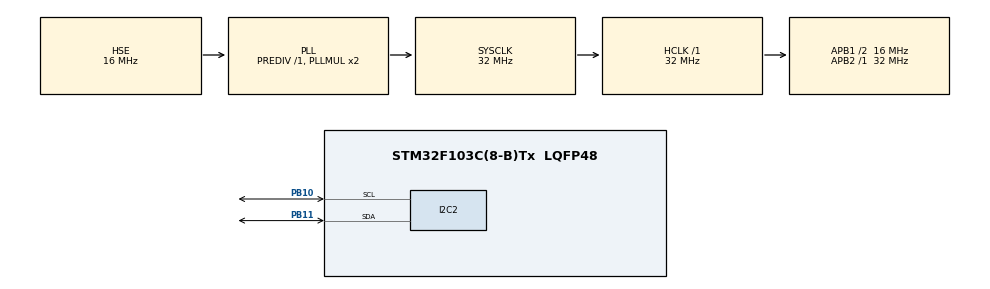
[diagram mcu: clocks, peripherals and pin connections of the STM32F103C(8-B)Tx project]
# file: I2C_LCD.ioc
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Mcu.Family=STM32F1
Mcu.Name=STM32F103C(8-B)Tx
Mcu.Package=LQFP48
NVIC.PriorityGroup=NVIC_PRIORITYGROUP_4
NVIC.TIM2_IRQn=true\:0\:0\:false\:false\:true\:true\:true\:true
PB10.Mode=I2C
PB10.Signal=I2C2_SCL
PB11.Mode=I2C
PB11.Signal=I2C2_SDA
PD0-OSC_IN.Mode=HSE-External-Oscillator
PD0-OSC_IN.Signal=RCC_OSC_IN
PD1-OSC_OUT.Mode=HSE-External-Oscillator
PD1-OSC_OUT.Signal=RCC_OSC_OUT
ProjectManager.HeapSize=0x200
ProjectManager.StackSize=0x400
ProjectManager.TargetToolchain=STM32CubeIDE
RCC.AHBFreq_Value=32000000
RCC.APB1CLKDivider=RCC_HCLK_DIV2
RCC.APB1Freq_Value=16000000
RCC.APB1TimFreq_Value=32000000
RCC.APB2Freq_Value=32000000
RCC.APB2TimFreq_Value=32000000
RCC.HCLKFreq_Value=32000000
RCC.HSE_VALUE=16000000
RCC.PLLSourceVirtual=RCC_PLLSOURCE_HSE
RCC.SYSCLKFreq_VALUE=32000000
RCC.SYSCLKSource=RCC_SYSCLKSOURCE_PLLCLK
RCC.USBFreq_Value=32000000
TIM2.Period=999
TIM2.Prescaler=32000
VP_SYS_VS_ND.Mode=No_Debug
VP_TIM2_VS_ClockSourceINT.Mode=Internal
board=custom

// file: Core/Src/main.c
/* USER CODE BEGIN Header */
/**
  ******************************************************************************
  * @file           : main.c
  * @brief          : Main program body
  ******************************************************************************
  * @attention
  *
  * Copyright (c) 2024 STMicroelectronics.
  * All rights reserved.
  *
  * This software is licensed under terms that can be found in the LICENSE file
  * in the root directory of this software component.
  * If no LICENSE file comes with this software, it is provided AS-IS.
  *
  ******************************************************************************
  */
/* USER CODE END Header */
#include "main.h"

/* USER CODE BEGIN Includes */
#include <stdint.h>
#include <stdio.h>
/* USER CODE END Includes */

/* USER CODE BEGIN PD */
//LCD Voreinstellungen
#define LCD_ADDR (0x27 << 1)
#define PIN_RS (1 << 0)
#define PIN_EN (1 << 2)
#define PIN_BL (1 << 3)
/* USER CODE END PD */

I2C_HandleTypeDef hi2c2;

TIM_HandleTypeDef htim2;

/* USER CODE BEGIN PV */
volatile uint8_t u1_TIM_Counter = 0;
/* USER CODE END PV */

void SystemClock_Config(void);
static void MX_GPIO_Init(void);
static void MX_I2C2_Init(void);
static void MX_TIM2_Init(void);
/* USER CODE BEGIN PFP */
//LCD-Funktionen

void send_LCD(uint8_t u1_data, uint8_t flag);
void send_LCD_CMD(uint8_t u1_data);
void send_LCD_TXT(uint8_t u1_data);
/* USER CODE END PFP */

int main(void)
{

  /* MCU Configuration--------------------------------------------------------*/

  /* Reset of all peripherals, Initializes the Flash interface and the Systick. */
  HAL_Init();

  /* Configure the system clock */
  SystemClock_Config();

  /* Initialize all configured peripherals */
  MX_GPIO_Init();
  MX_I2C2_Init();
  MX_TIM2_Init();
  /* USER CODE BEGIN 2 */
  //LCD-Konfiguration
  send_LCD_CMD(0x30);
  send_LCD_CMD(0xC);
  send_LCD_CMD(0x2);
  send_LCD_CMD(0x1);
  send_LCD_CMD(0x0E);

  //Buffer für obere Zeile
  unsigned char u1_charBuffer_top[16];
  //Buffer für untere Zeile
  unsigned char u1_charBuffer_down[16];

  //Begrüßungstext
  uint16_t u2_bytes_top  = sprintf((char*) &u1_charBuffer_top, "Hello");
  uint16_t u2_bytes_down = sprintf((char*) &u1_charBuffer_down, "Student");
  //obere Reihe
  send_LCD_CMD(0x80);
  for (uint8_t u1_i = 0; u1_i < u2_bytes_top; u1_i++){
	  send_LCD_TXT(u1_charBuffer_top[u1_i]);
  }
  HAL_Delay(100);
  //untere Reihe
  send_LCD_CMD(0xC0);
  for (uint8_t u1_i = 0; u1_i < u2_bytes_down; u1_i++){
	  send_LCD_TXT(u1_charBuffer_down[u1_i]);
  }
  HAL_Delay(5000);
  //Starte den Interrupt
  HAL_TIM_Base_Start_IT(&htim2);
  /* USER CODE END 2 */

  /* Infinite loop */
  /* USER CODE BEGIN WHILE */
  send_LCD_CMD(0x2);
  send_LCD_CMD(0x1);
  while (1)
  {
	  send_LCD_CMD(0x2);

	  //send_LCD_CMD(0x1);
	  uint16_t u2_bytes_top = sprintf((char*) &u1_charBuffer_top, "Zaehler: %3d", u1_TIM_Counter);
	  send_LCD_CMD(0x80);

	  for (uint8_t u1_i = 0; u1_i < u2_bytes_top; u1_i++){
	  			send_LCD_TXT(u1_charBuffer_top[u1_i]);
	  }

	 //HAL_Delay(1000);

    /* USER CODE END WHILE */

  }
}

void SystemClock_Config(void)
{
  RCC_OscInitTypeDef RCC_OscInitStruct = {0};
  RCC_ClkInitTypeDef RCC_ClkInitStruct = {0};

  /** Initializes the RCC Oscillators according to the specified parameters
  * in the RCC_OscInitTypeDef structure.
  */
  RCC_OscInitStruct.OscillatorType = RCC_OSCILLATORTYPE_HSE;
  RCC_OscInitStruct.HSEState = RCC_HSE_ON;
  RCC_OscInitStruct.HSEPredivValue = RCC_HSE_PREDIV_DIV1;
  RCC_OscInitStruct.HSIState = RCC_HSI_ON;
  RCC_OscInitStruct.PLL.PLLState = RCC_PLL_ON;
  RCC_OscInitStruct.PLL.PLLSource = RCC_PLLSOURCE_HSE;
  RCC_OscInitStruct.PLL.PLLMUL = RCC_PLL_MUL2;
  if (HAL_RCC_OscConfig(&RCC_OscInitStruct) != HAL_OK)
  {
    Error_Handler();
  }

  /** Initializes the CPU, AHB and APB buses clocks
  */
  RCC_ClkInitStruct.ClockType = RCC_CLOCKTYPE_HCLK|RCC_CLOCKTYPE_SYSCLK
                              |RCC_CLOCKTYPE_PCLK1|RCC_CLOCKTYPE_PCLK2;
  RCC_ClkInitStruct.SYSCLKSource = RCC_SYSCLKSOURCE_PLLCLK;
  RCC_ClkInitStruct.AHBCLKDivider = RCC_SYSCLK_DIV1;
  RCC_ClkInitStruct.APB1CLKDivider = RCC_HCLK_DIV2;
  RCC_ClkInitStruct.APB2CLKDivider = RCC_HCLK_DIV1;

  if (HAL_RCC_ClockConfig(&RCC_ClkInitStruct, FLASH_LATENCY_1) != HAL_OK)
  {
    Error_Handler();
  }
}

static void MX_I2C2_Init(void)
{

  hi2c2.Instance = I2C2;
  hi2c2.Init.ClockSpeed = 100000;
  hi2c2.Init.DutyCycle = I2C_DUTYCYCLE_2;
  hi2c2.Init.OwnAddress1 = 0;
  hi2c2.Init.AddressingMode = I2C_ADDRESSINGMODE_7BIT;
  hi2c2.Init.DualAddressMode = I2C_DUALADDRESS_DISABLE;
  hi2c2.Init.OwnAddress2 = 0;
  hi2c2.Init.GeneralCallMode = I2C_GENERALCALL_DISABLE;
  hi2c2.Init.NoStretchMode = I2C_NOSTRETCH_DISABLE;
  if (HAL_I2C_Init(&hi2c2) != HAL_OK)
  {
    Error_Handler();
  }

}

static void MX_TIM2_Init(void)
{

  TIM_ClockConfigTypeDef sClockSourceConfig = {0};
  TIM_MasterConfigTypeDef sMasterConfig = {0};

  htim2.Instance = TIM2;
  htim2.Init.Prescaler = 32000;
  htim2.Init.CounterMode = TIM_COUNTERMODE_UP;
  htim2.Init.Period = 999;
  htim2.Init.ClockDivision = TIM_CLOCKDIVISION_DIV1;
  htim2.Init.AutoReloadPreload = TIM_AUTORELOAD_PRELOAD_DISABLE;
  if (HAL_TIM_Base_Init(&htim2) != HAL_OK)
  {
    Error_Handler();
  }
  sClockSourceConfig.ClockSource = TIM_CLOCKSOURCE_INTERNAL;
  if (HAL_TIM_ConfigClockSource(&htim2, &sClockSourceConfig) != HAL_OK)
  {
    Error_Handler();
  }
  sMasterConfig.MasterOutputTrigger = TIM_TRGO_RESET;
  sMasterConfig.MasterSlaveMode = TIM_MASTERSLAVEMODE_DISABLE;
  if (HAL_TIMEx_MasterConfigSynchronization(&htim2, &sMasterConfig) != HAL_OK)
  {
    Error_Handler();
  }

}

static void MX_GPIO_Init(void)
{

  /* GPIO Ports Clock Enable */
  __HAL_RCC_GPIOD_CLK_ENABLE();
  __HAL_RCC_GPIOB_CLK_ENABLE();

}

/* USER CODE BEGIN 4 */
void HAL_TIM_PeriodElapsedCallback(TIM_HandleTypeDef *htim){

	if(u1_TIM_Counter == 255){
		u1_TIM_Counter = 0;
	}
	else{
		u1_TIM_Counter++;
	}

}

void send_LCD(uint8_t u1_data, uint8_t u1_flag){

	//Warte bis Device Ready

	while(1){
		HAL_StatusTypeDef res = HAL_I2C_IsDeviceReady(&hi2c2, LCD_ADDR, 1, HAL_MAX_DELAY);
		if(res == HAL_OK)
			break;
	}

	//Aufsplitten
	uint8_t u1_MSB;
	uint8_t u1_LSB;
	u1_MSB = u1_data & 0xF0;
	u1_LSB = (u1_data << 4) & 0xF0;

	//Datenepaket
	uint8_t u1_datapack[4];
	u1_datapack[0] = u1_MSB | u1_flag | PIN_BL | PIN_EN;
	u1_datapack[1] = u1_MSB | u1_flag | PIN_BL;
	u1_datapack[2] = u1_LSB | u1_flag | PIN_BL | PIN_EN;
	u1_datapack[3] = u1_LSB | u1_flag | PIN_BL;

	//Übertragung
	HAL_I2C_Master_Transmit(&hi2c2, (uint16_t)LCD_ADDR, u1_datapack,4,HAL_MAX_DELAY);

}

void send_LCD_CMD(uint8_t u1_data){
	send_LCD(u1_data,0);
}
void send_LCD_TXT(uint8_t u1_data){
	send_LCD(u1_data,PIN_RS);
}
/* USER CODE END 4 */

void Error_Handler(void)
{
  __disable_irq();
  while (1)
  {
  }
}
